# M0519AE_v1 register map
File version: 1.0
Registers are 32-bit, read-write, reset 0x0 unless marked. A register's access mark holds for its fields unless they carry their own. Offsets are from the block's base; [hi:lo] are bit positions; {n}, {i} and the like mark numbered series.

## INT — INT Register Map
Base 0x50000300
0x00 IRQ0_SRC ro reset not defined — IRQ0 (BOD) Interrupt Source Identity
  [0] BOD_INT — IRQ0 Source Identity
    0=IRQ0 source is not from BOD interrupt (BOD_INT); 1=IRQ0 source is from BOD interrupt (BOD_INT)
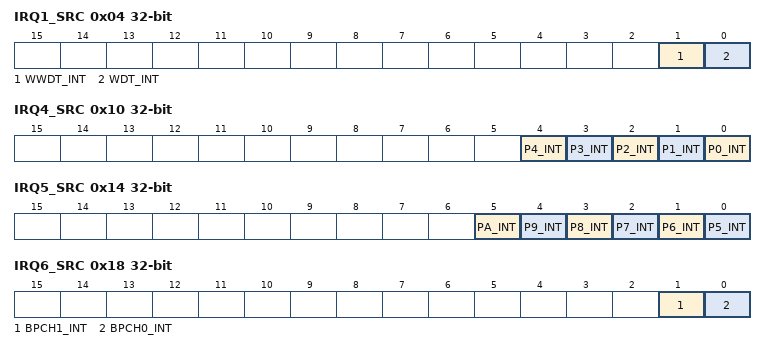
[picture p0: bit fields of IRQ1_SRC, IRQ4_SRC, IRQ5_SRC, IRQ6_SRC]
0x04 IRQ1_SRC ro reset not defined — IRQ1 (WDT) Interrupt Source Identity
  [1] WWDT_INT — IRQ1 Source Identity
    0=IRQ1 source is not from window-watchdog interrupt (WWDT _INT); 1=IRQ1 source is from window-watchdog interrupt (WWDT_INT)
  [0] WDT_INT — IRQ1 Source Identity
    0=IRQ1 source is not from watchdog interrupt (WDT _INT); 1=IRQ1 source is from watchdog interrupt (WDT_INT)
0x08 IRQ2_SRC ro reset not defined — IRQ2 (EINT0) Interrupt Source Identity
  [0] EINT0 — IRQ2 Source Identity
    0=IRQ2 source is not from external signal interrupt 0 from P3.2 (EINT0); 1=IRQ2 source is from external signal interrupt 0 from P3.2 (EINT0)
0x0C IRQ3_SRC ro reset not defined — IRQ3 (EINT1) Interrupt Source Identity
  [0] EINT1 — IRQ3 Source Identity
    0=IRQ3 source is not from external signal interrupt 1 from P3.3 (EINT1); 1=IRQ3 source is from external signal interrupt 1 from P3.3 (EINT1)
0x10 IRQ4_SRC ro reset not defined — IRQ4 (P0-P4) Interrupt Source Identity
  [n] P{n}_INT (n=0..4) — IRQ4 Source Identity
    0=IRQ4 source is not from P{n} interrupt (P{n}_INT); 1=IRQ4 source is from P{n} interrupt (P{n}_INT)
0x14 IRQ5_SRC ro reset not defined — IRQ5 (P5-PA) Interrupt Source Identity
  [5] PA_INT — IRQ5 Source Identity
    0=IRQ5 source is not from PA interrupt (PA_INT); 1=IRQ5 source is from PA interrupt (PA_INT)
  [n-5] P{n}_INT (n=5..9) — IRQ5 Source Identity
    0=IRQ5 source is not from P{n} interrupt (P{n}_INT); 1=IRQ5 source is from P{n} interrupt (P{n}_INT)
0x18 IRQ6_SRC ro reset not defined — IRQ6 (BPWM0) Interrupt Source Identity
  [1] BPCH1_INT — IRQ6 Source Identity
    0=IRQ6 source is not from BPWM0 channel 1 interrupt (BPCH1_INT); 1=IRQ6 source is from BPWM0 channel 1 interrupt (BPCH1_INT)
  [0] BPCH0_INT — IRQ6 Source Identity
    0=IRQ6 source is not from BPWM0 channel 0 interrupt (BPCH0_INT); 1=IRQ6 source is from BPWM0 channel 0 interrupt (BPCH0_INT)
0x1C IRQ7_SRC ro reset not defined — IRQ7 (EADC0) Interrupt Source Identity
  [0] EADC0_INT — IRQ7 Source Identity
    0=IRQ7 source is not from EADC0 interrupt (EADC0_INT); 1=IRQ7 source is from EADC0 interrupt (EADC0_INT)
{0x0+4i} IRQ{i}_SRC ro reset not defined (i=8..11) — IRQ{i} (TMR{i-8}) Interrupt Source Identity
  [0] TMR{i-8}_INT — IRQ{i} Source Identity
    0=IRQ{i} source is not from Timer{i-8} interrupt (TMR{i-8}_INT); 1=IRQ{i} source is from Timer{i-8} interrupt (TMR{i-8}_INT)
0x30 IRQ12_SRC ro reset not defined — IRQ12 (UART0) Interrupt Source Identity
  [0] UART0_INT — IRQ12 Source Identity
    0=IRQ12 source is not from UART0 interrupt (UART0_INT); 1=IRQ12 source is from UART0 interrupt (UART0_INT)
0x34 IRQ13_SRC ro reset not defined — IRQ13 (UART1) Interrupt Source Identity
  [0] UART1_INT — IRQ13 Source Identity
    0=IRQ13 source is not from UART1 interrupt (UART1_INT); 1=IRQ13 source is from UART1 interrupt (UART1_INT)
{0x0+4i} IRQ{i}_SRC ro reset not defined (i=14..16) — IRQ{i} (SPI{i-14}) Interrupt Source Identity
  [0] SPI{i-14}_INT — IRQ{i} Source Identity
    0=IRQ{i} source is not from SPI{i-14} interrupt (SPI{i-14}_INT); 1=IRQ{i} source is from SPI{i-14} interrupt (SPI{i-14}_INT)
0x48 IRQ18_SRC ro reset not defined — IRQ18 (I2C0) Interrupt Source Identity
  [0] I2C0_INT — IRQ18 Source Identity
    0=IRQ18 source is not from I2C0 interrupt (I2C0_INT); 1=IRQ18 source is from I2C0 interrupt (I2C0_INT)
0x4C IRQ19_SRC ro reset not defined — IRQ19 (CKD) Interrupt Source Identity
  [0] CKD_INT — IRQ19 Source Identity
    0=IRQ19 source is not from CKD interrupt (CKD_INT); 1=IRQ19 source is from CKD interrupt (CKD_INT)
0x54 IRQ21_SRC ro reset not defined — IRQ21 (EPWM0) Interrupt Source Identity
  [0] EPWM0_INT — IRQ21 Source Identity
    0=IRQ21 source is not from EPWM0 interrupt (EPWM0_INT); 1=IRQ21 source is from EPWM0 interrupt (EPWM0_INT)
0x58 IRQ22_SRC ro reset not defined — IRQ22 (EPWM1) Interrupt Source Identity
  [0] EPWM1_INT — IRQ22 Source Identity
    0=IRQ22 source is not from EPWM1 interrupt (EPWM1_INT); 1=IRQ22 source is from EPWM1 interrupt (EPWM1_INT)
0x5C IRQ23_SRC ro reset not defined — IRQ23 (ECAP0) Interrupt Source Identity
  [0] ECAP0_INT — IRQ23 Source Identity
    0=IRQ23 source is not from ECAP0 interrupt (ECAP0_INT); 1=IRQ23 source is from ECAP0 interrupt (ECAP0_INT)
0x60 IRQ24_SRC ro reset not defined — IRQ24 (ECAP1) Interrupt Source Identity
  [0] ECAP1_INT — IRQ24 Source Identity
    0=IRQ24 source is not from ECAP1 interrupt (ECAP1_INT); 1=IRQ24 source is from ECAP1 interrupt (ECAP1_INT)
0x64 IRQ25_SRC ro reset not defined — IRQ25 (ACMP) Interrupt Source Identity
  [0] ACMP_INT — IRQ25 Source Identity
    0=IRQ25 source is not from ACMP interrupt (ACMP_INT); 1=IRQ25 source is from ACMP interrupt (ACMP_INT)
0x70 IRQ28_SRC ro reset not defined — IRQ28 (PWRWU) Interrupt Source Identity
  [0] PWRWU_INT — IRQ28 Source Identity
    0=IRQ28 source is not from PWRWU interrupt (PWRWU_INT); 1=IRQ28 source is from PWREU interrupt (PWRWU_INT)
{0x0+4i} IRQ{i}_SRC ro reset not defined (i=29..31) — IRQ{i} (EADC{i-28}) Interrupt Source Identity
  [0] EADC{i-28}_INT — IRQ{i} Source Identity
    0=IRQ{i} source is not from EADC{i-28} interrupt (EADC{i-28}_INT); 1=IRQ{i} source is from EADC{i-28} interrupt (EADC{i-28}_INT)
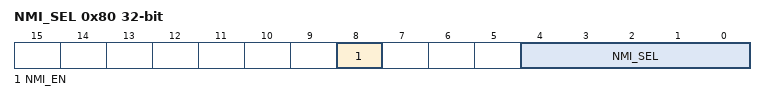
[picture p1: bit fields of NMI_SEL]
0x80 NMI_SEL — NMI Interrupt Source Select Control Register
  [8] NMI_EN — NMI Interrupt Enable Bit (Write Protect). Note: This bit is write protected bit. Refer to the REGWRPROT register.
    0=IRQ0~31 assigned to NMI Disabled. (NMI still can be software triggered by setting its pending flag.); 1=IRQ0~31 assigned to NMI Enabled
  [4:0] NMI_SEL — NMI Interrupt Source Selection. The NMI interrupt to Cortex-M0 can be selected from one of IRQ0~IRQ31 by setting NMI_SEL with IRQ number. The default NMI interrupt is assigned as IRQ0 interrupt if NMI is enabled by setting NMI_SEL[8].
0x84 MCU_IRQ — MCU Interrupt Request Source Register
  [31:0] MCU_IRQ — MCU IRQ Source Register. The MCU_IRQ collects all the interrupts from the peripherals and generates the synchronous interrupt to Cortex-M0. The MCU_IRQ collects all interrupts from each peripheral and synchronizes them and then interrupts the Cortex-M0. When the MCU_IRQ[n] is 0, it means no interrupt is assert. Write 1 to generate an interrupt to Cortex-M0 NVIC[n]. When the MCU_IRQ[n] is 1, it means an interrupt is assert. Write 1 to clear the interrupt and MCU_IRQ[n].
0x88 MCU_IRQCR — MCU Interrupt Request Control Register
  [0] FAST_IRQ — Fast IRQ Latency Enable Bit
    0=MCU IRQ latency is fixed at 13 HCLK, MCU will enter IRQ handler after this fixed latency when interrupt happened; 1=MCU IRQ latency will not fixed, MCU will enter IRQ handler as soon as possible when interrupt happened
